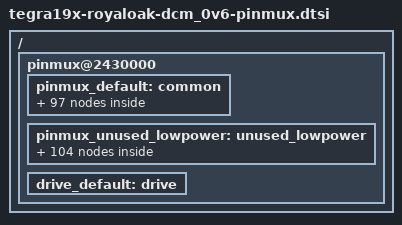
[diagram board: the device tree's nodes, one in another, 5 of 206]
/*This dtsi file was generated by dcm_0v6.xlsm Revision: 1.06 */
/*
 * Copyright (c) 2017, NVIDIA CORPORATION.  All rights reserved.
 *
 * This program is free software; you can redistribute it and/or modify
 * it under the terms of the GNU General Public License as published by
 * the Free Software Foundation; either version 2 of the License, or
 * (at your option) any later version.
 *
 * This program is distributed in the hope that it will be useful, but WITHOUT
 * ANY WARRANTY; without even the implied warranty of MERCHANTABILITY or
 * FITNESS FOR A PARTICULAR PURPOSE.  See the GNU General Public License for
 * more details.
 */

#include <dt-bindings/pinctrl/pinctrl-tegra.h>

/ {
	pinmux@2430000 {
		pinctrl-names = "default", "drive", "unused";
		pinctrl-0 = <&pinmux_default>;
		pinctrl-1 = <&drive_default>;
		pinctrl-2 = <&pinmux_unused_lowpower>;

		pinmux_default: common {
			/* SFIO Pin Configuration */
			eqos_txc_pe0 {
				nvidia,pins = "eqos_txc_pe0";
				nvidia,function = "eqos";
				nvidia,pull = <TEGRA_PIN_PULL_NONE>;
				nvidia,tristate = <TEGRA_PIN_DISABLE>;
				nvidia,enable-input = <TEGRA_PIN_DISABLE>;
			};

			eqos_td0_pe1 {
				nvidia,pins = "eqos_td0_pe1";
				nvidia,function = "eqos";
				nvidia,pull = <TEGRA_PIN_PULL_NONE>;
				nvidia,tristate = <TEGRA_PIN_DISABLE>;
				nvidia,enable-input = <TEGRA_PIN_DISABLE>;
			};

			eqos_td1_pe2 {
				nvidia,pins = "eqos_td1_pe2";
				nvidia,function = "eqos";
				nvidia,pull = <TEGRA_PIN_PULL_NONE>;
				nvidia,tristate = <TEGRA_PIN_DISABLE>;
				nvidia,enable-input = <TEGRA_PIN_DISABLE>;
			};

			eqos_td2_pe3 {
				nvidia,pins = "eqos_td2_pe3";
				nvidia,function = "eqos";
				nvidia,pull = <TEGRA_PIN_PULL_NONE>;
				nvidia,tristate = <TEGRA_PIN_DISABLE>;
				nvidia,enable-input = <TEGRA_PIN_DISABLE>;
			};

			eqos_td3_pe4 {
				nvidia,pins = "eqos_td3_pe4";
				nvidia,function = "eqos";
				nvidia,pull = <TEGRA_PIN_PULL_NONE>;
				nvidia,tristate = <TEGRA_PIN_DISABLE>;
				nvidia,enable-input = <TEGRA_PIN_DISABLE>;
			};

			eqos_tx_ctl_pe5 {
				nvidia,pins = "eqos_tx_ctl_pe5";
				nvidia,function = "eqos";
				nvidia,pull = <TEGRA_PIN_PULL_NONE>;
				nvidia,tristate = <TEGRA_PIN_DISABLE>;
				nvidia,enable-input = <TEGRA_PIN_DISABLE>;
			};

			eqos_rd0_pe6 {
				nvidia,pins = "eqos_rd0_pe6";
				nvidia,function = "eqos";
				nvidia,pull = <TEGRA_PIN_PULL_NONE>;
				nvidia,tristate = <TEGRA_PIN_ENABLE>;
				nvidia,enable-input = <TEGRA_PIN_ENABLE>;
			};

			eqos_rd1_pe7 {
				nvidia,pins = "eqos_rd1_pe7";
				nvidia,function = "eqos";
				nvidia,pull = <TEGRA_PIN_PULL_NONE>;
				nvidia,tristate = <TEGRA_PIN_ENABLE>;
				nvidia,enable-input = <TEGRA_PIN_ENABLE>;
			};

			eqos_rd2_pf0 {
				nvidia,pins = "eqos_rd2_pf0";
				nvidia,function = "eqos";
				nvidia,pull = <TEGRA_PIN_PULL_NONE>;
				nvidia,tristate = <TEGRA_PIN_ENABLE>;
				nvidia,enable-input = <TEGRA_PIN_ENABLE>;
			};

			eqos_rd3_pf1 {
				nvidia,pins = "eqos_rd3_pf1";
				nvidia,function = "eqos";
				nvidia,pull = <TEGRA_PIN_PULL_NONE>;
				nvidia,tristate = <TEGRA_PIN_ENABLE>;
				nvidia,enable-input = <TEGRA_PIN_ENABLE>;
			};

			eqos_rx_ctl_pf2 {
				nvidia,pins = "eqos_rx_ctl_pf2";
				nvidia,function = "eqos";
				nvidia,pull = <TEGRA_PIN_PULL_NONE>;
				nvidia,tristate = <TEGRA_PIN_ENABLE>;
				nvidia,enable-input = <TEGRA_PIN_ENABLE>;
			};

			eqos_rxc_pf3 {
				nvidia,pins = "eqos_rxc_pf3";
				nvidia,function = "eqos";
				nvidia,pull = <TEGRA_PIN_PULL_NONE>;
				nvidia,tristate = <TEGRA_PIN_ENABLE>;
				nvidia,enable-input = <TEGRA_PIN_ENABLE>;
			};

			eqos_sma_mdio_pf4 {
				nvidia,pins = "eqos_sma_mdio_pf4";
				nvidia,function = "eqos";
				nvidia,pull = <TEGRA_PIN_PULL_NONE>;
				nvidia,tristate = <TEGRA_PIN_DISABLE>;
				nvidia,enable-input = <TEGRA_PIN_ENABLE>;
			};

			eqos_sma_mdc_pf5 {
				nvidia,pins = "eqos_sma_mdc_pf5";
				nvidia,function = "eqos";
				nvidia,pull = <TEGRA_PIN_PULL_NONE>;
				nvidia,tristate = <TEGRA_PIN_DISABLE>;
				nvidia,enable-input = <TEGRA_PIN_DISABLE>;
			};

			qspi0_sck_pc0 {
				nvidia,pins = "qspi0_sck_pc0";
				nvidia,function = "qspi0";
				nvidia,pull = <TEGRA_PIN_PULL_NONE>;
				nvidia,tristate = <TEGRA_PIN_DISABLE>;
				nvidia,enable-input = <TEGRA_PIN_ENABLE>;
				nvidia,loopback = <TEGRA_PIN_ENABLE>;
			};

			qspi0_cs_n_pc1 {
				nvidia,pins = "qspi0_cs_n_pc1";
				nvidia,function = "qspi0";
				nvidia,pull = <TEGRA_PIN_PULL_NONE>;
				nvidia,tristate = <TEGRA_PIN_DISABLE>;
				nvidia,enable-input = <TEGRA_PIN_DISABLE>;
			};

			qspi0_io0_pc2 {
				nvidia,pins = "qspi0_io0_pc2";
				nvidia,function = "qspi0";
				nvidia,pull = <TEGRA_PIN_PULL_NONE>;
				nvidia,tristate = <TEGRA_PIN_DISABLE>;
				nvidia,enable-input = <TEGRA_PIN_ENABLE>;
			};

			qspi0_io1_pc3 {
				nvidia,pins = "qspi0_io1_pc3";
				nvidia,function = "qspi0";
				nvidia,pull = <TEGRA_PIN_PULL_NONE>;
				nvidia,tristate = <TEGRA_PIN_DISABLE>;
				nvidia,enable-input = <TEGRA_PIN_ENABLE>;
			};

			qspi0_io2_pc4 {
				nvidia,pins = "qspi0_io2_pc4";
				nvidia,function = "qspi0";
				nvidia,pull = <TEGRA_PIN_PULL_NONE>;
				nvidia,tristate = <TEGRA_PIN_DISABLE>;
				nvidia,enable-input = <TEGRA_PIN_ENABLE>;
			};

			qspi0_io3_pc5 {
				nvidia,pins = "qspi0_io3_pc5";
				nvidia,function = "qspi0";
				nvidia,pull = <TEGRA_PIN_PULL_NONE>;
				nvidia,tristate = <TEGRA_PIN_DISABLE>;
				nvidia,enable-input = <TEGRA_PIN_ENABLE>;
			};

			qspi1_sck_pc6 {
				nvidia,pins = "qspi1_sck_pc6";
				nvidia,function = "qspi1";
				nvidia,pull = <TEGRA_PIN_PULL_NONE>;
				nvidia,tristate = <TEGRA_PIN_DISABLE>;
				nvidia,enable-input = <TEGRA_PIN_ENABLE>;
				nvidia,loopback = <TEGRA_PIN_ENABLE>;
			};

			qspi1_cs_n_pc7 {
				nvidia,pins = "qspi1_cs_n_pc7";
				nvidia,function = "qspi1";
				nvidia,pull = <TEGRA_PIN_PULL_NONE>;
				nvidia,tristate = <TEGRA_PIN_DISABLE>;
				nvidia,enable-input = <TEGRA_PIN_DISABLE>;
			};

			qspi1_io0_pd0 {
				nvidia,pins = "qspi1_io0_pd0";
				nvidia,function = "qspi1";
				nvidia,pull = <TEGRA_PIN_PULL_NONE>;
				nvidia,tristate = <TEGRA_PIN_DISABLE>;
				nvidia,enable-input = <TEGRA_PIN_ENABLE>;
			};

			qspi1_io1_pd1 {
				nvidia,pins = "qspi1_io1_pd1";
				nvidia,function = "qspi1";
				nvidia,pull = <TEGRA_PIN_PULL_NONE>;
				nvidia,tristate = <TEGRA_PIN_DISABLE>;
				nvidia,enable-input = <TEGRA_PIN_ENABLE>;
			};

			qspi1_io2_pd2 {
				nvidia,pins = "qspi1_io2_pd2";
				nvidia,function = "qspi1";
				nvidia,pull = <TEGRA_PIN_PULL_NONE>;
				nvidia,tristate = <TEGRA_PIN_DISABLE>;
				nvidia,enable-input = <TEGRA_PIN_ENABLE>;
			};

			qspi1_io3_pd3 {
				nvidia,pins = "qspi1_io3_pd3";
				nvidia,function = "qspi1";
				nvidia,pull = <TEGRA_PIN_PULL_NONE>;
				nvidia,tristate = <TEGRA_PIN_DISABLE>;
				nvidia,enable-input = <TEGRA_PIN_ENABLE>;
			};

			sdmmc4_clk {
				nvidia,pins = "sdmmc4_clk";
				nvidia,function = "sdmmc4";
				nvidia,pull = <TEGRA_PIN_PULL_NONE>;
				nvidia,tristate = <TEGRA_PIN_DISABLE>;
				nvidia,enable-input = <TEGRA_PIN_ENABLE>;
				nvidia,loopback = <TEGRA_PIN_ENABLE>;
			};

			sdmmc4_cmd {
				nvidia,pins = "sdmmc4_cmd";
				nvidia,function = "sdmmc4";
				nvidia,pull = <TEGRA_PIN_PULL_NONE>;
				nvidia,tristate = <TEGRA_PIN_DISABLE>;
				nvidia,enable-input = <TEGRA_PIN_ENABLE>;
			};

			sdmmc4_dat0 {
				nvidia,pins = "sdmmc4_dat0";
				nvidia,function = "sdmmc4";
				nvidia,pull = <TEGRA_PIN_PULL_UP>;
				nvidia,tristate = <TEGRA_PIN_DISABLE>;
				nvidia,enable-input = <TEGRA_PIN_ENABLE>;
			};

			sdmmc4_dat1 {
				nvidia,pins = "sdmmc4_dat1";
				nvidia,function = "sdmmc4";
				nvidia,pull = <TEGRA_PIN_PULL_UP>;
				nvidia,tristate = <TEGRA_PIN_DISABLE>;
				nvidia,enable-input = <TEGRA_PIN_ENABLE>;
			};

			sdmmc4_dat2 {
				nvidia,pins = "sdmmc4_dat2";
				nvidia,function = "sdmmc4";
				nvidia,pull = <TEGRA_PIN_PULL_UP>;
				nvidia,tristate = <TEGRA_PIN_DISABLE>;
				nvidia,enable-input = <TEGRA_PIN_ENABLE>;
			};

			sdmmc4_dat3 {
				nvidia,pins = "sdmmc4_dat3";
				nvidia,function = "sdmmc4";
				nvidia,pull = <TEGRA_PIN_PULL_UP>;
				nvidia,tristate = <TEGRA_PIN_DISABLE>;
				nvidia,enable-input = <TEGRA_PIN_ENABLE>;
			};

			sdmmc4_dat4 {
				nvidia,pins = "sdmmc4_dat4";
				nvidia,function = "sdmmc4";
				nvidia,pull = <TEGRA_PIN_PULL_UP>;
				nvidia,tristate = <TEGRA_PIN_DISABLE>;
				nvidia,enable-input = <TEGRA_PIN_ENABLE>;
			};

			sdmmc4_dat5 {
				nvidia,pins = "sdmmc4_dat5";
				nvidia,function = "sdmmc4";
				nvidia,pull = <TEGRA_PIN_PULL_UP>;
				nvidia,tristate = <TEGRA_PIN_DISABLE>;
				nvidia,enable-input = <TEGRA_PIN_ENABLE>;
			};

			sdmmc4_dat6 {
				nvidia,pins = "sdmmc4_dat6";
				nvidia,function = "sdmmc4";
				nvidia,pull = <TEGRA_PIN_PULL_UP>;
				nvidia,tristate = <TEGRA_PIN_DISABLE>;
				nvidia,enable-input = <TEGRA_PIN_ENABLE>;
			};

			sdmmc4_dat7 {
				nvidia,pins = "sdmmc4_dat7";
				nvidia,function = "sdmmc4";
				nvidia,pull = <TEGRA_PIN_PULL_UP>;
				nvidia,tristate = <TEGRA_PIN_DISABLE>;
				nvidia,enable-input = <TEGRA_PIN_ENABLE>;
			};

			sdmmc4_dqs {
				nvidia,pins = "sdmmc4_dqs";
				nvidia,function = "sdmmc4";
				nvidia,pull = <TEGRA_PIN_PULL_NONE>;
				nvidia,tristate = <TEGRA_PIN_ENABLE>;
				nvidia,enable-input = <TEGRA_PIN_ENABLE>;
			};

			soc_gpio10_pg6 {
				nvidia,pins = "soc_gpio10_pg6";
				nvidia,function = "gp";
				nvidia,pull = <TEGRA_PIN_PULL_NONE>;
				nvidia,tristate = <TEGRA_PIN_ENABLE>;
				nvidia,enable-input = <TEGRA_PIN_DISABLE>;
				nvidia,lpdr = <TEGRA_PIN_DISABLE>;
			};

			soc_gpio13_ph1 {
				nvidia,pins = "soc_gpio13_ph1";
				nvidia,function = "gp";
				nvidia,pull = <TEGRA_PIN_PULL_NONE>;
				nvidia,tristate = <TEGRA_PIN_ENABLE>;
				nvidia,enable-input = <TEGRA_PIN_DISABLE>;
				nvidia,lpdr = <TEGRA_PIN_DISABLE>;
			};

			gen1_i2c_scl_pi3 {
				nvidia,pins = "gen1_i2c_scl_pi3";
				nvidia,function = "i2c1";
				nvidia,pull = <TEGRA_PIN_PULL_NONE>;
				nvidia,tristate = <TEGRA_PIN_DISABLE>;
				nvidia,enable-input = <TEGRA_PIN_ENABLE>;
				nvidia,io-high-voltage = <TEGRA_PIN_DISABLE>;
				nvidia,lpdr = <TEGRA_PIN_DISABLE>;
			};

			gen1_i2c_sda_pi4 {
				nvidia,pins = "gen1_i2c_sda_pi4";
				nvidia,function = "i2c1";
				nvidia,pull = <TEGRA_PIN_PULL_NONE>;
				nvidia,tristate = <TEGRA_PIN_DISABLE>;
				nvidia,enable-input = <TEGRA_PIN_ENABLE>;
				nvidia,io-high-voltage = <TEGRA_PIN_DISABLE>;
				nvidia,lpdr = <TEGRA_PIN_DISABLE>;
			};

			gp_pwm2_px2 {
				nvidia,pins = "gp_pwm2_px2";
				nvidia,function = "gp";
				nvidia,pull = <TEGRA_PIN_PULL_NONE>;
				nvidia,tristate = <TEGRA_PIN_ENABLE>;
				nvidia,enable-input = <TEGRA_PIN_DISABLE>;
				nvidia,lpdr = <TEGRA_PIN_DISABLE>;
			};

			gp_pwm3_px3 {
				nvidia,pins = "gp_pwm3_px3";
				nvidia,function = "gp";
				nvidia,pull = <TEGRA_PIN_PULL_NONE>;
				nvidia,tristate = <TEGRA_PIN_ENABLE>;
				nvidia,enable-input = <TEGRA_PIN_DISABLE>;
				nvidia,lpdr = <TEGRA_PIN_DISABLE>;
			};

			uart2_tx_px4 {
				nvidia,pins = "uart2_tx_px4";
				nvidia,function = "uartb";
				nvidia,pull = <TEGRA_PIN_PULL_NONE>;
				nvidia,tristate = <TEGRA_PIN_DISABLE>;
				nvidia,enable-input = <TEGRA_PIN_DISABLE>;
				nvidia,io-high-voltage = <TEGRA_PIN_DISABLE>;
				nvidia,lpdr = <TEGRA_PIN_DISABLE>;
			};

			uart2_rx_px5 {
				nvidia,pins = "uart2_rx_px5";
				nvidia,function = "uartb";
				nvidia,pull = <TEGRA_PIN_PULL_UP>;
				nvidia,tristate = <TEGRA_PIN_ENABLE>;
				nvidia,enable-input = <TEGRA_PIN_ENABLE>;
				nvidia,io-high-voltage = <TEGRA_PIN_DISABLE>;
				nvidia,lpdr = <TEGRA_PIN_DISABLE>;
			};

			spi1_sck_pz3 {
				nvidia,pins = "spi1_sck_pz3";
				nvidia,function = "spi1";
				nvidia,pull = <TEGRA_PIN_PULL_DOWN>;
				nvidia,tristate = <TEGRA_PIN_DISABLE>;
				nvidia,enable-input = <TEGRA_PIN_DISABLE>;
				nvidia,lpdr = <TEGRA_PIN_DISABLE>;
			};

			spi1_miso_pz4 {
				nvidia,pins = "spi1_miso_pz4";
				nvidia,function = "spi1";
				nvidia,pull = <TEGRA_PIN_PULL_DOWN>;
				nvidia,tristate = <TEGRA_PIN_ENABLE>;
				nvidia,enable-input = <TEGRA_PIN_ENABLE>;
				nvidia,lpdr = <TEGRA_PIN_DISABLE>;
			};

			spi1_mosi_pz5 {
				nvidia,pins = "spi1_mosi_pz5";
				nvidia,function = "spi1";
				nvidia,pull = <TEGRA_PIN_PULL_DOWN>;
				nvidia,tristate = <TEGRA_PIN_DISABLE>;
				nvidia,enable-input = <TEGRA_PIN_DISABLE>;
				nvidia,lpdr = <TEGRA_PIN_DISABLE>;
			};

			spi1_cs0_pz6 {
				nvidia,pins = "spi1_cs0_pz6";
				nvidia,function = "spi1";
				nvidia,pull = <TEGRA_PIN_PULL_NONE>;
				nvidia,tristate = <TEGRA_PIN_DISABLE>;
				nvidia,enable-input = <TEGRA_PIN_DISABLE>;
				nvidia,lpdr = <TEGRA_PIN_DISABLE>;
			};

			shutdown_n {
				nvidia,pins = "shutdown_n";
				nvidia,function = "shutdown";
				nvidia,pull = <TEGRA_PIN_PULL_NONE>;
				nvidia,tristate = <TEGRA_PIN_DISABLE>;
				nvidia,enable-input = <TEGRA_PIN_DISABLE>;
				nvidia,io-high-voltage = <TEGRA_PIN_DISABLE>;
				nvidia,lpdr = <TEGRA_PIN_ENABLE>;
			};

			pwr_i2c_scl_pee5 {
				nvidia,pins = "pwr_i2c_scl_pee5";
				nvidia,function = "i2c5";
				nvidia,pull = <TEGRA_PIN_PULL_NONE>;
				nvidia,tristate = <TEGRA_PIN_DISABLE>;
				nvidia,enable-input = <TEGRA_PIN_ENABLE>;
				nvidia,io-high-voltage = <TEGRA_PIN_DISABLE>;
				nvidia,lpdr = <TEGRA_PIN_DISABLE>;
			};

			pwr_i2c_sda_pee6 {
				nvidia,pins = "pwr_i2c_sda_pee6";
				nvidia,function = "i2c5";
				nvidia,pull = <TEGRA_PIN_PULL_NONE>;
				nvidia,tristate = <TEGRA_PIN_DISABLE>;
				nvidia,enable-input = <TEGRA_PIN_ENABLE>;
				nvidia,io-high-voltage = <TEGRA_PIN_DISABLE>;
				nvidia,lpdr = <TEGRA_PIN_DISABLE>;
			};

			batt_oc_pee3 {
				nvidia,pins = "batt_oc_pee3";
				nvidia,function = "soc";
				nvidia,pull = <TEGRA_PIN_PULL_NONE>;
				nvidia,tristate = <TEGRA_PIN_ENABLE>;
				nvidia,enable-input = <TEGRA_PIN_ENABLE>;
				nvidia,lpdr = <TEGRA_PIN_DISABLE>;
			};

			spi2_sck_pcc0 {
				nvidia,pins = "spi2_sck_pcc0";
				nvidia,function = "spi2";
				nvidia,pull = <TEGRA_PIN_PULL_NONE>;
				nvidia,tristate = <TEGRA_PIN_DISABLE>;
				nvidia,enable-input = <TEGRA_PIN_DISABLE>;
				nvidia,io-high-voltage = <TEGRA_PIN_DISABLE>;
				nvidia,lpdr = <TEGRA_PIN_DISABLE>;
			};

			spi2_miso_pcc1 {
				nvidia,pins = "spi2_miso_pcc1";
				nvidia,function = "spi2";
				nvidia,pull = <TEGRA_PIN_PULL_NONE>;
				nvidia,tristate = <TEGRA_PIN_ENABLE>;
				nvidia,enable-input = <TEGRA_PIN_ENABLE>;
				nvidia,io-high-voltage = <TEGRA_PIN_DISABLE>;
				nvidia,lpdr = <TEGRA_PIN_DISABLE>;
			};

			spi2_mosi_pcc2 {
				nvidia,pins = "spi2_mosi_pcc2";
				nvidia,function = "spi2";
				nvidia,pull = <TEGRA_PIN_PULL_NONE>;
				nvidia,tristate = <TEGRA_PIN_DISABLE>;
				nvidia,enable-input = <TEGRA_PIN_DISABLE>;
				nvidia,io-high-voltage = <TEGRA_PIN_DISABLE>;
				nvidia,lpdr = <TEGRA_PIN_DISABLE>;
			};

			spi2_cs0_pcc3 {
				nvidia,pins = "spi2_cs0_pcc3";
				nvidia,function = "spi2";
				nvidia,pull = <TEGRA_PIN_PULL_NONE>;
				nvidia,tristate = <TEGRA_PIN_DISABLE>;
				nvidia,enable-input = <TEGRA_PIN_DISABLE>;
				nvidia,io-high-voltage = <TEGRA_PIN_DISABLE>;
				nvidia,lpdr = <TEGRA_PIN_DISABLE>;
			};

			touch_clk_pcc4 {
				nvidia,pins = "touch_clk_pcc4";
				nvidia,function = "gp";
				nvidia,pull = <TEGRA_PIN_PULL_NONE>;
				nvidia,tristate = <TEGRA_PIN_DISABLE>;
				nvidia,enable-input = <TEGRA_PIN_DISABLE>;
				nvidia,lpdr = <TEGRA_PIN_DISABLE>;
			};

			uart3_tx_pcc5 {
				nvidia,pins = "uart3_tx_pcc5";
				nvidia,function = "uartc";
				nvidia,pull = <TEGRA_PIN_PULL_NONE>;
				nvidia,tristate = <TEGRA_PIN_DISABLE>;
				nvidia,enable-input = <TEGRA_PIN_DISABLE>;
				nvidia,io-high-voltage = <TEGRA_PIN_DISABLE>;
				nvidia,lpdr = <TEGRA_PIN_DISABLE>;
			};

			uart3_rx_pcc6 {
				nvidia,pins = "uart3_rx_pcc6";
				nvidia,function = "uartc";
				nvidia,pull = <TEGRA_PIN_PULL_UP>;
				nvidia,tristate = <TEGRA_PIN_ENABLE>;
				nvidia,enable-input = <TEGRA_PIN_ENABLE>;
				nvidia,io-high-voltage = <TEGRA_PIN_DISABLE>;
				nvidia,lpdr = <TEGRA_PIN_DISABLE>;
			};

			gen2_i2c_scl_pcc7 {
				nvidia,pins = "gen2_i2c_scl_pcc7";
				nvidia,function = "i2c2";
				nvidia,pull = <TEGRA_PIN_PULL_NONE>;
				nvidia,tristate = <TEGRA_PIN_DISABLE>;
				nvidia,enable-input = <TEGRA_PIN_ENABLE>;
				nvidia,io-high-voltage = <TEGRA_PIN_DISABLE>;
				nvidia,lpdr = <TEGRA_PIN_ENABLE>;
			};

			gen2_i2c_sda_pdd0 {
				nvidia,pins = "gen2_i2c_sda_pdd0";
				nvidia,function = "i2c2";
				nvidia,pull = <TEGRA_PIN_PULL_NONE>;
				nvidia,tristate = <TEGRA_PIN_DISABLE>;
				nvidia,enable-input = <TEGRA_PIN_ENABLE>;
				nvidia,io-high-voltage = <TEGRA_PIN_DISABLE>;
				nvidia,lpdr = <TEGRA_PIN_ENABLE>;
			};

			soc_gpio07_pp7 {
				nvidia,pins = "soc_gpio07_pp7";
				nvidia,function = "soc";
				nvidia,pull = <TEGRA_PIN_PULL_UP>;
				nvidia,tristate = <TEGRA_PIN_ENABLE>;
				nvidia,enable-input = <TEGRA_PIN_ENABLE>;
				nvidia,io-high-voltage = <TEGRA_PIN_DISABLE>;
				nvidia,lpdr = <TEGRA_PIN_DISABLE>;
			};

			soc_gpio22_pq2 {
				nvidia,pins = "soc_gpio22_pq2";
				nvidia,function = "nv";
				nvidia,pull = <TEGRA_PIN_PULL_NONE>;
				nvidia,tristate = <TEGRA_PIN_ENABLE>;
				nvidia,enable-input = <TEGRA_PIN_ENABLE>;
				nvidia,lpdr = <TEGRA_PIN_DISABLE>;
			};

			soc_gpio54_pn1 {
				nvidia,pins = "soc_gpio54_pn1";
				nvidia,function = "gp";
				nvidia,pull = <TEGRA_PIN_PULL_NONE>;
				nvidia,tristate = <TEGRA_PIN_DISABLE>;
				nvidia,enable-input = <TEGRA_PIN_DISABLE>;
				nvidia,lpdr = <TEGRA_PIN_DISABLE>;
			};

			/* GPIO Pin Configuration */
			soc_gpio30_ps5 {
				nvidia,pins = "soc_gpio30_ps5";
				nvidia,function = "rsvd0";
				nvidia,pull = <TEGRA_PIN_PULL_UP>;
				nvidia,tristate = <TEGRA_PIN_ENABLE>;
				nvidia,enable-input = <TEGRA_PIN_ENABLE>;
				nvidia,lpdr = <TEGRA_PIN_DISABLE>;
			};

			soc_gpio31_ps6 {
				nvidia,pins = "soc_gpio31_ps6";
				nvidia,function = "rsvd0";
				nvidia,pull = <TEGRA_PIN_PULL_UP>;
				nvidia,tristate = <TEGRA_PIN_ENABLE>;
				nvidia,enable-input = <TEGRA_PIN_ENABLE>;
				nvidia,lpdr = <TEGRA_PIN_DISABLE>;
			};

			soc_gpio32_ps7 {
				nvidia,pins = "soc_gpio32_ps7";
				nvidia,function = "rsvd0";
				nvidia,pull = <TEGRA_PIN_PULL_UP>;
				nvidia,tristate = <TEGRA_PIN_ENABLE>;
				nvidia,enable-input = <TEGRA_PIN_ENABLE>;
				nvidia,lpdr = <TEGRA_PIN_DISABLE>;
			};

			soc_gpio00_pg0 {
				nvidia,pins = "soc_gpio00_pg0";
				nvidia,function = "rsvd0";
				nvidia,pull = <TEGRA_PIN_PULL_NONE>;
				nvidia,tristate = <TEGRA_PIN_ENABLE>;
				nvidia,enable-input = <TEGRA_PIN_ENABLE>;
				nvidia,lpdr = <TEGRA_PIN_DISABLE>;
			};

			soc_gpio01_pg1 {
				nvidia,pins = "soc_gpio01_pg1";
				nvidia,function = "rsvd0";
				nvidia,pull = <TEGRA_PIN_PULL_NONE>;
				nvidia,tristate = <TEGRA_PIN_ENABLE>;
				nvidia,enable-input = <TEGRA_PIN_ENABLE>;
				nvidia,lpdr = <TEGRA_PIN_DISABLE>;
			};

			soc_gpio08_pg4 {
				nvidia,pins = "soc_gpio08_pg4";
				nvidia,function = "rsvd0";
				nvidia,pull = <TEGRA_PIN_PULL_NONE>;
				nvidia,tristate = <TEGRA_PIN_ENABLE>;
				nvidia,enable-input = <TEGRA_PIN_ENABLE>;
				nvidia,lpdr = <TEGRA_PIN_DISABLE>;
			};

			soc_gpio09_pg5 {
				nvidia,pins = "soc_gpio09_pg5";
				nvidia,function = "rsvd0";
				nvidia,pull = <TEGRA_PIN_PULL_NONE>;
				nvidia,tristate = <TEGRA_PIN_DISABLE>;
				nvidia,enable-input = <TEGRA_PIN_DISABLE>;
				nvidia,lpdr = <TEGRA_PIN_DISABLE>;
			};

			soc_gpio14_ph2 {
				nvidia,pins = "soc_gpio14_ph2";
				nvidia,function = "rsvd0";
				nvidia,pull = <TEGRA_PIN_PULL_NONE>;
				nvidia,tristate = <TEGRA_PIN_ENABLE>;
				nvidia,enable-input = <TEGRA_PIN_ENABLE>;
				nvidia,lpdr = <TEGRA_PIN_DISABLE>;
			};

			gpu_pwr_req_px0 {
				nvidia,pins = "gpu_pwr_req_px0";
				nvidia,function = "rsvd0";
				nvidia,pull = <TEGRA_PIN_PULL_NONE>;
				nvidia,tristate = <TEGRA_PIN_DISABLE>;
				nvidia,enable-input = <TEGRA_PIN_DISABLE>;
				nvidia,lpdr = <TEGRA_PIN_DISABLE>;
			};

			cv_pwr_req_px1 {
				nvidia,pins = "cv_pwr_req_px1";
				nvidia,function = "rsvd0";
				nvidia,pull = <TEGRA_PIN_PULL_NONE>;
				nvidia,tristate = <TEGRA_PIN_DISABLE>;
				nvidia,enable-input = <TEGRA_PIN_DISABLE>;
				nvidia,lpdr = <TEGRA_PIN_DISABLE>;
			};

			usb_vbus_en0_pz1 {
				nvidia,pins = "usb_vbus_en0_pz1";
				nvidia,function = "rsvd1";
				nvidia,pull = <TEGRA_PIN_PULL_NONE>;
				nvidia,tristate = <TEGRA_PIN_DISABLE>;
				nvidia,enable-input = <TEGRA_PIN_DISABLE>;
				nvidia,io-high-voltage = <TEGRA_PIN_DISABLE>;
				nvidia,lpdr = <TEGRA_PIN_DISABLE>;
			};

			usb_vbus_en1_pz2 {
				nvidia,pins = "usb_vbus_en1_pz2";
				nvidia,function = "rsvd1";
				nvidia,pull = <TEGRA_PIN_PULL_NONE>;
				nvidia,tristate = <TEGRA_PIN_ENABLE>;
				nvidia,enable-input = <TEGRA_PIN_ENABLE>;
				nvidia,io-high-voltage = <TEGRA_PIN_DISABLE>;
				nvidia,lpdr = <TEGRA_PIN_DISABLE>;
			};

			safe_state_pee0 {
				nvidia,pins = "safe_state_pee0";
				nvidia,function = "rsvd1";
				nvidia,pull = <TEGRA_PIN_PULL_UP>;
				nvidia,tristate = <TEGRA_PIN_DISABLE>;
				nvidia,enable-input = <TEGRA_PIN_DISABLE>;
				nvidia,io-high-voltage = <TEGRA_PIN_DISABLE>;
				nvidia,lpdr = <TEGRA_PIN_DISABLE>;
			};

			power_on_pee4 {
				nvidia,pins = "power_on_pee4";
				nvidia,function = "rsvd0";
				nvidia,pull = <TEGRA_PIN_PULL_NONE>;
				nvidia,tristate = <TEGRA_PIN_ENABLE>;
				nvidia,enable-input = <TEGRA_PIN_ENABLE>;
				nvidia,lpdr = <TEGRA_PIN_DISABLE>;
			};

			can0_stb_paa4 {
				nvidia,pins = "can0_stb_paa4";
				nvidia,function = "rsvd0";
				nvidia,pull = <TEGRA_PIN_PULL_NONE>;
				nvidia,tristate = <TEGRA_PIN_DISABLE>;
				nvidia,enable-input = <TEGRA_PIN_DISABLE>;
			};

			can0_err_paa7 {
				nvidia,pins = "can0_err_paa7";
				nvidia,function = "rsvd0";
				nvidia,pull = <TEGRA_PIN_PULL_UP>;
				nvidia,tristate = <TEGRA_PIN_DISABLE>;
				nvidia,enable-input = <TEGRA_PIN_ENABLE>;
			};

			can1_en_pbb1 {
				nvidia,pins = "can1_en_pbb1";
				nvidia,function = "rsvd0";
				nvidia,pull = <TEGRA_PIN_PULL_NONE>;
				nvidia,tristate = <TEGRA_PIN_ENABLE>;
				nvidia,enable-input = <TEGRA_PIN_DISABLE>;
			};

			can1_wake_pbb2 {
				nvidia,pins = "can1_wake_pbb2";
				nvidia,function = "rsvd0";
				nvidia,pull = <TEGRA_PIN_PULL_NONE>;
				nvidia,tristate = <TEGRA_PIN_ENABLE>;
				nvidia,enable-input = <TEGRA_PIN_ENABLE>;
			};

			soc_gpio04_pp4 {
				nvidia,pins = "soc_gpio04_pp4";
				nvidia,function = "rsvd0";
				nvidia,pull = <TEGRA_PIN_PULL_NONE>;
				nvidia,tristate = <TEGRA_PIN_ENABLE>;
				nvidia,enable-input = <TEGRA_PIN_ENABLE>;
				nvidia,lpdr = <TEGRA_PIN_DISABLE>;
			};

			soc_gpio05_pp5 {
				nvidia,pins = "soc_gpio05_pp5";
				nvidia,function = "rsvd0";
				nvidia,pull = <TEGRA_PIN_PULL_UP>;
				nvidia,tristate = <TEGRA_PIN_ENABLE>;
				nvidia,enable-input = <TEGRA_PIN_ENABLE>;
				nvidia,lpdr = <TEGRA_PIN_DISABLE>;
			};

			soc_gpio06_pp6 {
				nvidia,pins = "soc_gpio06_pp6";
				nvidia,function = "rsvd0";
				nvidia,pull = <TEGRA_PIN_PULL_NONE>;
				nvidia,tristate = <TEGRA_PIN_ENABLE>;
				nvidia,enable-input = <TEGRA_PIN_ENABLE>;
				nvidia,lpdr = <TEGRA_PIN_DISABLE>;
			};

			soc_gpio20_pq0 {
				nvidia,pins = "soc_gpio20_pq0";
				nvidia,function = "rsvd0";
				nvidia,pull = <TEGRA_PIN_PULL_NONE>;
				nvidia,tristate = <TEGRA_PIN_ENABLE>;
				nvidia,enable-input = <TEGRA_PIN_ENABLE>;
				nvidia,lpdr = <TEGRA_PIN_DISABLE>;
			};

			soc_gpio21_pq1 {
				nvidia,pins = "soc_gpio21_pq1";
				nvidia,function = "rsvd0";
				nvidia,pull = <TEGRA_PIN_PULL_UP>;
				nvidia,tristate = <TEGRA_PIN_ENABLE>;
				nvidia,enable-input = <TEGRA_PIN_ENABLE>;
				nvidia,lpdr = <TEGRA_PIN_DISABLE>;
			};

			soc_gpio40_pq4 {
				nvidia,pins = "soc_gpio40_pq4";
				nvidia,function = "rsvd2";
				nvidia,pull = <TEGRA_PIN_PULL_UP>;
				nvidia,tristate = <TEGRA_PIN_ENABLE>;
				nvidia,enable-input = <TEGRA_PIN_ENABLE>;
				nvidia,io-high-voltage = <TEGRA_PIN_ENABLE>;
				nvidia,lpdr = <TEGRA_PIN_DISABLE>;
			};

			dap6_sclk_pa0 {
				nvidia,pins = "dap6_sclk_pa0";
				nvidia,function = "rsvd2";
				nvidia,pull = <TEGRA_PIN_PULL_NONE>;
				nvidia,tristate = <TEGRA_PIN_ENABLE>;
				nvidia,enable-input = <TEGRA_PIN_DISABLE>;
			};

			dap6_din_pa2 {
				nvidia,pins = "dap6_din_pa2";
				nvidia,function = "rsvd2";
				nvidia,pull = <TEGRA_PIN_PULL_NONE>;
				nvidia,tristate = <TEGRA_PIN_ENABLE>;
				nvidia,enable-input = <TEGRA_PIN_DISABLE>;
			};

			cpu_pwr_req_0_pb0 {
				nvidia,pins = "cpu_pwr_req_0_pb0";
				nvidia,function = "rsvd0";
				nvidia,pull = <TEGRA_PIN_PULL_NONE>;
				nvidia,tristate = <TEGRA_PIN_DISABLE>;
				nvidia,enable-input = <TEGRA_PIN_DISABLE>;
				nvidia,lpdr = <TEGRA_PIN_DISABLE>;
			};

			cpu_pwr_req_1_pb1 {
				nvidia,pins = "cpu_pwr_req_1_pb1";
				nvidia,function = "rsvd0";
				nvidia,pull = <TEGRA_PIN_PULL_NONE>;
				nvidia,tristate = <TEGRA_PIN_DISABLE>;
				nvidia,enable-input = <TEGRA_PIN_DISABLE>;
				nvidia,lpdr = <TEGRA_PIN_DISABLE>;
			};

			dp_aux_ch3_hpd_pm3 {
				nvidia,pins = "dp_aux_ch3_hpd_pm3";
				nvidia,function = "rsvd2";
				nvidia,pull = <TEGRA_PIN_PULL_NONE>;
				nvidia,tristate = <TEGRA_PIN_DISABLE>;
				nvidia,enable-input = <TEGRA_PIN_DISABLE>;
				nvidia,io-high-voltage = <TEGRA_PIN_DISABLE>;
			};

			soc_gpio51_pm6 {
				nvidia,pins = "soc_gpio51_pm6";
				nvidia,function = "rsvd0";
				nvidia,pull = <TEGRA_PIN_PULL_NONE>;
				nvidia,tristate = <TEGRA_PIN_DISABLE>;
				nvidia,enable-input = <TEGRA_PIN_DISABLE>;
				nvidia,lpdr = <TEGRA_PIN_DISABLE>;
			};

			soc_gpio53_pn0 {
				nvidia,pins = "soc_gpio53_pn0";
				nvidia,function = "rsvd0";
				nvidia,pull = <TEGRA_PIN_PULL_NONE>;
				nvidia,tristate = <TEGRA_PIN_ENABLE>;
				nvidia,enable-input = <TEGRA_PIN_ENABLE>;
				nvidia,lpdr = <TEGRA_PIN_DISABLE>;
			};

			soc_gpio55_pn2 {
				nvidia,pins = "soc_gpio55_pn2";
				nvidia,function = "rsvd0";
				nvidia,pull = <TEGRA_PIN_PULL_NONE>;
				nvidia,tristate = <TEGRA_PIN_DISABLE>;
				nvidia,enable-input = <TEGRA_PIN_DISABLE>;
				nvidia,lpdr = <TEGRA_PIN_DISABLE>;
			};
		};

		pinmux_unused_lowpower: unused_lowpower {
			dap1_sclk_ps0 {
				nvidia,pins = "dap1_sclk_ps0";
				nvidia,function = "rsvd1";
				nvidia,pull = <TEGRA_PIN_PULL_DOWN>;
				nvidia,tristate = <TEGRA_PIN_ENABLE>;
				nvidia,enable-input = <TEGRA_PIN_ENABLE>;
				nvidia,lpdr = <TEGRA_PIN_DISABLE>;
			};

			dap1_dout_ps1 {
				nvidia,pins = "dap1_dout_ps1";
				nvidia,function = "rsvd1";
				nvidia,pull = <TEGRA_PIN_PULL_DOWN>;
				nvidia,tristate = <TEGRA_PIN_ENABLE>;
				nvidia,enable-input = <TEGRA_PIN_DISABLE>;
				nvidia,lpdr = <TEGRA_PIN_DISABLE>;
			};

			dap1_din_ps2 {
				nvidia,pins = "dap1_din_ps2";
				nvidia,function = "rsvd1";
				nvidia,pull = <TEGRA_PIN_PULL_DOWN>;
				nvidia,tristate = <TEGRA_PIN_ENABLE>;
				nvidia,enable-input = <TEGRA_PIN_DISABLE>;
				nvidia,lpdr = <TEGRA_PIN_DISABLE>;
			};

			dap1_fs_ps3 {
				nvidia,pins = "dap1_fs_ps3";
				nvidia,function = "rsvd1";
				nvidia,pull = <TEGRA_PIN_PULL_DOWN>;
				nvidia,tristate = <TEGRA_PIN_ENABLE>;
				nvidia,enable-input = <TEGRA_PIN_ENABLE>;
				nvidia,lpdr = <TEGRA_PIN_DISABLE>;
			};

			aud_mclk_ps4 {
				nvidia,pins = "aud_mclk_ps4";
				nvidia,function = "rsvd1";
				nvidia,pull = <TEGRA_PIN_PULL_DOWN>;
				nvidia,tristate = <TEGRA_PIN_ENABLE>;
				nvidia,enable-input = <TEGRA_PIN_DISABLE>;
				nvidia,lpdr = <TEGRA_PIN_DISABLE>;
			};

			soc_gpio33_pt0 {
				nvidia,pins = "soc_gpio33_pt0";
				nvidia,function = "rsvd0";
				nvidia,pull = <TEGRA_PIN_PULL_DOWN>;
				nvidia,tristate = <TEGRA_PIN_ENABLE>;
				nvidia,enable-input = <TEGRA_PIN_DISABLE>;
				nvidia,lpdr = <TEGRA_PIN_DISABLE>;
			};

			dap3_sclk_pt1 {
				nvidia,pins = "dap3_sclk_pt1";
				nvidia,function = "rsvd2";
				nvidia,pull = <TEGRA_PIN_PULL_DOWN>;
				nvidia,tristate = <TEGRA_PIN_ENABLE>;
				nvidia,enable-input = <TEGRA_PIN_DISABLE>;
				nvidia,lpdr = <TEGRA_PIN_DISABLE>;
			};

			dap3_dout_pt2 {
				nvidia,pins = "dap3_dout_pt2";
				nvidia,function = "rsvd2";
				nvidia,pull = <TEGRA_PIN_PULL_DOWN>;
				nvidia,tristate = <TEGRA_PIN_ENABLE>;
				nvidia,enable-input = <TEGRA_PIN_DISABLE>;
				nvidia,lpdr = <TEGRA_PIN_DISABLE>;
			};

			dap3_din_pt3 {
				nvidia,pins = "dap3_din_pt3";
				nvidia,function = "rsvd2";
				nvidia,pull = <TEGRA_PIN_PULL_DOWN>;
				nvidia,tristate = <TEGRA_PIN_ENABLE>;
				nvidia,enable-input = <TEGRA_PIN_DISABLE>;
				nvidia,lpdr = <TEGRA_PIN_DISABLE>;
			};

			dap3_fs_pt4 {
				nvidia,pins = "dap3_fs_pt4";
				nvidia,function = "rsvd2";
				nvidia,pull = <TEGRA_PIN_PULL_DOWN>;
				nvidia,tristate = <TEGRA_PIN_ENABLE>;
				nvidia,enable-input = <TEGRA_PIN_DISABLE>;
				nvidia,lpdr = <TEGRA_PIN_DISABLE>;
			};

			dap5_sclk_pt5 {
				nvidia,pins = "dap5_sclk_pt5";
				nvidia,function = "rsvd2";
				nvidia,pull = <TEGRA_PIN_PULL_DOWN>;
				nvidia,tristate = <TEGRA_PIN_ENABLE>;
				nvidia,enable-input = <TEGRA_PIN_DISABLE>;
				nvidia,lpdr = <TEGRA_PIN_DISABLE>;
			};

			dap5_dout_pt6 {
				nvidia,pins = "dap5_dout_pt6";
				nvidia,function = "rsvd2";
				nvidia,pull = <TEGRA_PIN_PULL_DOWN>;
				nvidia,tristate = <TEGRA_PIN_ENABLE>;
				nvidia,enable-input = <TEGRA_PIN_DISABLE>;
				nvidia,lpdr = <TEGRA_PIN_DISABLE>;
			};

			dap5_din_pt7 {
				nvidia,pins = "dap5_din_pt7";
				nvidia,function = "rsvd3";
				nvidia,pull = <TEGRA_PIN_PULL_DOWN>;
				nvidia,tristate = <TEGRA_PIN_ENABLE>;
				nvidia,enable-input = <TEGRA_PIN_DISABLE>;
				nvidia,lpdr = <TEGRA_PIN_DISABLE>;
			};

			dap5_fs_pu0 {
				nvidia,pins = "dap5_fs_pu0";
				nvidia,function = "rsvd3";
				nvidia,pull = <TEGRA_PIN_PULL_DOWN>;
				nvidia,tristate = <TEGRA_PIN_ENABLE>;
				nvidia,enable-input = <TEGRA_PIN_DISABLE>;
				nvidia,lpdr = <TEGRA_PIN_DISABLE>;
			};

			sdmmc1_clk_pj0 {
				nvidia,pins = "sdmmc1_clk_pj0";
				nvidia,function = "rsvd1";
				nvidia,pull = <TEGRA_PIN_PULL_DOWN>;
				nvidia,tristate = <TEGRA_PIN_ENABLE>;
				nvidia,enable-input = <TEGRA_PIN_DISABLE>;
				nvidia,loopback = <TEGRA_PIN_ENABLE>;
			};

			sdmmc1_cmd_pj1 {
				nvidia,pins = "sdmmc1_cmd_pj1";
				nvidia,function = "rsvd1";
				nvidia,pull = <TEGRA_PIN_PULL_DOWN>;
				nvidia,tristate = <TEGRA_PIN_ENABLE>;
				nvidia,enable-input = <TEGRA_PIN_DISABLE>;
			};

			sdmmc1_dat0_pj2 {
				nvidia,pins = "sdmmc1_dat0_pj2";
				nvidia,function = "rsvd1";
				nvidia,pull = <TEGRA_PIN_PULL_DOWN>;
				nvidia,tristate = <TEGRA_PIN_ENABLE>;
				nvidia,enable-input = <TEGRA_PIN_DISABLE>;
			};

			sdmmc1_dat1_pj3 {
				nvidia,pins = "sdmmc1_dat1_pj3";
				nvidia,function = "rsvd1";
				nvidia,pull = <TEGRA_PIN_PULL_DOWN>;
				nvidia,tristate = <TEGRA_PIN_ENABLE>;
				nvidia,enable-input = <TEGRA_PIN_DISABLE>;
			};

			sdmmc1_dat2_pj4 {
				nvidia,pins = "sdmmc1_dat2_pj4";
				nvidia,function = "rsvd1";
				nvidia,pull = <TEGRA_PIN_PULL_DOWN>;
				nvidia,tristate = <TEGRA_PIN_ENABLE>;
				nvidia,enable-input = <TEGRA_PIN_DISABLE>;
			};

			sdmmc1_dat3_pj5 {
				nvidia,pins = "sdmmc1_dat3_pj5";
				nvidia,function = "rsvd1";
				nvidia,pull = <TEGRA_PIN_PULL_DOWN>;
				nvidia,tristate = <TEGRA_PIN_ENABLE>;
				nvidia,enable-input = <TEGRA_PIN_DISABLE>;
			};

			sdmmc3_clk_po0 {
				nvidia,pins = "sdmmc3_clk_po0";
				nvidia,function = "rsvd1";
				nvidia,pull = <TEGRA_PIN_PULL_DOWN>;
				nvidia,tristate = <TEGRA_PIN_ENABLE>;
				nvidia,enable-input = <TEGRA_PIN_DISABLE>;
				nvidia,loopback = <TEGRA_PIN_DISABLE>;
			};

			sdmmc3_cmd_po1 {
				nvidia,pins = "sdmmc3_cmd_po1";
				nvidia,function = "rsvd1";
				nvidia,pull = <TEGRA_PIN_PULL_DOWN>;
				nvidia,tristate = <TEGRA_PIN_ENABLE>;
				nvidia,enable-input = <TEGRA_PIN_DISABLE>;
			};

			sdmmc3_dat0_po2 {
				nvidia,pins = "sdmmc3_dat0_po2";
				nvidia,function = "rsvd1";
				nvidia,pull = <TEGRA_PIN_PULL_DOWN>;
				nvidia,tristate = <TEGRA_PIN_ENABLE>;
				nvidia,enable-input = <TEGRA_PIN_DISABLE>;
			};

			sdmmc3_dat1_po3 {
				nvidia,pins = "sdmmc3_dat1_po3";
				nvidia,function = "rsvd1";
				nvidia,pull = <TEGRA_PIN_PULL_DOWN>;
				nvidia,tristate = <TEGRA_PIN_ENABLE>;
				nvidia,enable-input = <TEGRA_PIN_DISABLE>;
			};

			sdmmc3_dat2_po4 {
				nvidia,pins = "sdmmc3_dat2_po4";
				nvidia,function = "rsvd1";
				nvidia,pull = <TEGRA_PIN_PULL_DOWN>;
				nvidia,tristate = <TEGRA_PIN_ENABLE>;
				nvidia,enable-input = <TEGRA_PIN_DISABLE>;
			};

			sdmmc3_dat3_po5 {
				nvidia,pins = "sdmmc3_dat3_po5";
				nvidia,function = "rsvd1";
				nvidia,pull = <TEGRA_PIN_PULL_DOWN>;
				nvidia,tristate = <TEGRA_PIN_ENABLE>;
				nvidia,enable-input = <TEGRA_PIN_DISABLE>;
			};

			soc_gpio02_pg2 {
				nvidia,pins = "soc_gpio02_pg2";
				nvidia,function = "rsvd0";
				nvidia,pull = <TEGRA_PIN_PULL_DOWN>;
				nvidia,tristate = <TEGRA_PIN_ENABLE>;
				nvidia,enable-input = <TEGRA_PIN_DISABLE>;
				nvidia,lpdr = <TEGRA_PIN_DISABLE>;
			};

			soc_gpio03_pg3 {
				nvidia,pins = "soc_gpio03_pg3";
				nvidia,function = "rsvd0";
				nvidia,pull = <TEGRA_PIN_PULL_DOWN>;
				nvidia,tristate = <TEGRA_PIN_ENABLE>;
				nvidia,enable-input = <TEGRA_PIN_DISABLE>;
				nvidia,lpdr = <TEGRA_PIN_DISABLE>;
			};

			soc_gpio11_pg7 {
				nvidia,pins = "soc_gpio11_pg7";
				nvidia,function = "rsvd0";
				nvidia,pull = <TEGRA_PIN_PULL_DOWN>;
				nvidia,tristate = <TEGRA_PIN_ENABLE>;
				nvidia,enable-input = <TEGRA_PIN_DISABLE>;
				nvidia,lpdr = <TEGRA_PIN_DISABLE>;
			};

			soc_gpio12_ph0 {
				nvidia,pins = "soc_gpio12_ph0";
				nvidia,function = "rsvd0";
				nvidia,pull = <TEGRA_PIN_PULL_DOWN>;
				nvidia,tristate = <TEGRA_PIN_ENABLE>;
				nvidia,enable-input = <TEGRA_PIN_DISABLE>;
				nvidia,lpdr = <TEGRA_PIN_DISABLE>;
			};

			uart4_tx_ph3 {
				nvidia,pins = "uart4_tx_ph3";
				nvidia,function = "rsvd1";
				nvidia,pull = <TEGRA_PIN_PULL_DOWN>;
				nvidia,tristate = <TEGRA_PIN_ENABLE>;
				nvidia,enable-input = <TEGRA_PIN_DISABLE>;
				nvidia,lpdr = <TEGRA_PIN_DISABLE>;
			};

			uart4_rx_ph4 {
				nvidia,pins = "uart4_rx_ph4";
				nvidia,function = "rsvd1";
				nvidia,pull = <TEGRA_PIN_PULL_DOWN>;
				nvidia,tristate = <TEGRA_PIN_ENABLE>;
				nvidia,enable-input = <TEGRA_PIN_DISABLE>;
				nvidia,lpdr = <TEGRA_PIN_DISABLE>;
			};

			uart4_rts_ph5 {
				nvidia,pins = "uart4_rts_ph5";
				nvidia,function = "rsvd1";
				nvidia,pull = <TEGRA_PIN_PULL_DOWN>;
				nvidia,tristate = <TEGRA_PIN_ENABLE>;
				nvidia,enable-input = <TEGRA_PIN_DISABLE>;
				nvidia,lpdr = <TEGRA_PIN_DISABLE>;
			};

			uart4_cts_ph6 {
				nvidia,pins = "uart4_cts_ph6";
				nvidia,function = "rsvd1";
				nvidia,pull = <TEGRA_PIN_PULL_DOWN>;
				nvidia,tristate = <TEGRA_PIN_ENABLE>;
				nvidia,enable-input = <TEGRA_PIN_DISABLE>;
				nvidia,lpdr = <TEGRA_PIN_DISABLE>;
			};

			dap2_sclk_ph7 {
				nvidia,pins = "dap2_sclk_ph7";
				nvidia,function = "rsvd1";
				nvidia,pull = <TEGRA_PIN_PULL_DOWN>;
				nvidia,tristate = <TEGRA_PIN_ENABLE>;
				nvidia,enable-input = <TEGRA_PIN_DISABLE>;
				nvidia,lpdr = <TEGRA_PIN_DISABLE>;
			};

			dap2_dout_pi0 {
				nvidia,pins = "dap2_dout_pi0";
				nvidia,function = "rsvd1";
				nvidia,pull = <TEGRA_PIN_PULL_DOWN>;
				nvidia,tristate = <TEGRA_PIN_ENABLE>;
				nvidia,enable-input = <TEGRA_PIN_DISABLE>;
				nvidia,lpdr = <TEGRA_PIN_DISABLE>;
			};

			dap2_din_pi1 {
				nvidia,pins = "dap2_din_pi1";
				nvidia,function = "rsvd1";
				nvidia,pull = <TEGRA_PIN_PULL_DOWN>;
				nvidia,tristate = <TEGRA_PIN_ENABLE>;
				nvidia,enable-input = <TEGRA_PIN_DISABLE>;
				nvidia,lpdr = <TEGRA_PIN_DISABLE>;
			};

			dap2_fs_pi2 {
				nvidia,pins = "dap2_fs_pi2";
				nvidia,function = "rsvd1";
				nvidia,pull = <TEGRA_PIN_PULL_DOWN>;
				nvidia,tristate = <TEGRA_PIN_ENABLE>;
				nvidia,enable-input = <TEGRA_PIN_DISABLE>;
				nvidia,lpdr = <TEGRA_PIN_DISABLE>;
			};

			uart2_rts_px6 {
				nvidia,pins = "uart2_rts_px6";
				nvidia,function = "rsvd1";
				nvidia,pull = <TEGRA_PIN_PULL_DOWN>;
				nvidia,tristate = <TEGRA_PIN_ENABLE>;
				nvidia,enable-input = <TEGRA_PIN_DISABLE>;
				nvidia,lpdr = <TEGRA_PIN_DISABLE>;
			};

			uart2_cts_px7 {
				nvidia,pins = "uart2_cts_px7";
				nvidia,function = "rsvd1";
				nvidia,pull = <TEGRA_PIN_PULL_DOWN>;
				nvidia,tristate = <TEGRA_PIN_ENABLE>;
				nvidia,enable-input = <TEGRA_PIN_DISABLE>;
				nvidia,lpdr = <TEGRA_PIN_DISABLE>;
			};

			spi3_sck_py0 {
				nvidia,pins = "spi3_sck_py0";
				nvidia,function = "rsvd1";
				nvidia,pull = <TEGRA_PIN_PULL_DOWN>;
				nvidia,tristate = <TEGRA_PIN_ENABLE>;
				nvidia,enable-input = <TEGRA_PIN_DISABLE>;
				nvidia,io-high-voltage = <TEGRA_PIN_DISABLE>;
				nvidia,lpdr = <TEGRA_PIN_DISABLE>;
			};

			spi3_miso_py1 {
				nvidia,pins = "spi3_miso_py1";
				nvidia,function = "rsvd1";
				nvidia,pull = <TEGRA_PIN_PULL_DOWN>;
				nvidia,tristate = <TEGRA_PIN_ENABLE>;
				nvidia,enable-input = <TEGRA_PIN_DISABLE>;
				nvidia,io-high-voltage = <TEGRA_PIN_DISABLE>;
				nvidia,lpdr = <TEGRA_PIN_DISABLE>;
			};

			spi3_mosi_py2 {
				nvidia,pins = "spi3_mosi_py2";
				nvidia,function = "rsvd1";
				nvidia,pull = <TEGRA_PIN_PULL_DOWN>;
				nvidia,tristate = <TEGRA_PIN_ENABLE>;
				nvidia,enable-input = <TEGRA_PIN_DISABLE>;
				nvidia,io-high-voltage = <TEGRA_PIN_DISABLE>;
				nvidia,lpdr = <TEGRA_PIN_DISABLE>;
			};

			spi3_cs0_py3 {
				nvidia,pins = "spi3_cs0_py3";
				nvidia,function = "rsvd1";
				nvidia,pull = <TEGRA_PIN_PULL_DOWN>;
				nvidia,tristate = <TEGRA_PIN_ENABLE>;
				nvidia,enable-input = <TEGRA_PIN_DISABLE>;
				nvidia,io-high-voltage = <TEGRA_PIN_DISABLE>;
				nvidia,lpdr = <TEGRA_PIN_DISABLE>;
			};

			spi3_cs1_py4 {
				nvidia,pins = "spi3_cs1_py4";
				nvidia,function = "rsvd1";
				nvidia,pull = <TEGRA_PIN_PULL_DOWN>;
				nvidia,tristate = <TEGRA_PIN_ENABLE>;
				nvidia,enable-input = <TEGRA_PIN_DISABLE>;
				nvidia,io-high-voltage = <TEGRA_PIN_DISABLE>;
				nvidia,lpdr = <TEGRA_PIN_DISABLE>;
			};

			uart5_tx_py5 {
				nvidia,pins = "uart5_tx_py5";
				nvidia,function = "rsvd1";
				nvidia,pull = <TEGRA_PIN_PULL_DOWN>;
				nvidia,tristate = <TEGRA_PIN_ENABLE>;
				nvidia,enable-input = <TEGRA_PIN_DISABLE>;
				nvidia,lpdr = <TEGRA_PIN_DISABLE>;
			};

			uart5_rx_py6 {
				nvidia,pins = "uart5_rx_py6";
				nvidia,function = "rsvd1";
				nvidia,pull = <TEGRA_PIN_PULL_DOWN>;
				nvidia,tristate = <TEGRA_PIN_ENABLE>;
				nvidia,enable-input = <TEGRA_PIN_DISABLE>;
				nvidia,lpdr = <TEGRA_PIN_DISABLE>;
			};

			uart5_rts_py7 {
				nvidia,pins = "uart5_rts_py7";
				nvidia,function = "rsvd1";
				nvidia,pull = <TEGRA_PIN_PULL_DOWN>;
				nvidia,tristate = <TEGRA_PIN_ENABLE>;
				nvidia,enable-input = <TEGRA_PIN_DISABLE>;
				nvidia,lpdr = <TEGRA_PIN_DISABLE>;
			};

			uart5_cts_pz0 {
				nvidia,pins = "uart5_cts_pz0";
				nvidia,function = "rsvd1";
				nvidia,pull = <TEGRA_PIN_PULL_DOWN>;
				nvidia,tristate = <TEGRA_PIN_ENABLE>;
				nvidia,enable-input = <TEGRA_PIN_DISABLE>;
				nvidia,lpdr = <TEGRA_PIN_DISABLE>;
			};

			spi1_cs1_pz7 {
				nvidia,pins = "spi1_cs1_pz7";
				nvidia,function = "rsvd1";
				nvidia,pull = <TEGRA_PIN_PULL_DOWN>;
				nvidia,tristate = <TEGRA_PIN_ENABLE>;
				nvidia,enable-input = <TEGRA_PIN_DISABLE>;
				nvidia,lpdr = <TEGRA_PIN_DISABLE>;
			};

			vcomp_alert_pee1 {
				nvidia,pins = "vcomp_alert_pee1";
				nvidia,function = "rsvd1";
				nvidia,pull = <TEGRA_PIN_PULL_DOWN>;
				nvidia,tristate = <TEGRA_PIN_ENABLE>;
				nvidia,enable-input = <TEGRA_PIN_DISABLE>;
				nvidia,lpdr = <TEGRA_PIN_DISABLE>;
			};

			ao_retention_n_pee2 {
				nvidia,pins = "ao_retention_n_pee2";
				nvidia,function = "rsvd1";
				nvidia,pull = <TEGRA_PIN_PULL_DOWN>;
				nvidia,tristate = <TEGRA_PIN_ENABLE>;
				nvidia,enable-input = <TEGRA_PIN_DISABLE>;
				nvidia,io-high-voltage = <TEGRA_PIN_DISABLE>;
				nvidia,lpdr = <TEGRA_PIN_DISABLE>;
			};

			can1_dout_paa0 {
				nvidia,pins = "can1_dout_paa0";
				nvidia,function = "rsvd1";
				nvidia,pull = <TEGRA_PIN_PULL_DOWN>;
				nvidia,tristate = <TEGRA_PIN_ENABLE>;
				nvidia,enable-input = <TEGRA_PIN_DISABLE>;
			};

			can1_din_paa1 {
				nvidia,pins = "can1_din_paa1";
				nvidia,function = "rsvd1";
				nvidia,pull = <TEGRA_PIN_PULL_DOWN>;
				nvidia,tristate = <TEGRA_PIN_ENABLE>;
				nvidia,enable-input = <TEGRA_PIN_DISABLE>;
			};

			can0_dout_paa2 {
				nvidia,pins = "can0_dout_paa2";
				nvidia,function = "rsvd1";
				nvidia,pull = <TEGRA_PIN_PULL_DOWN>;
				nvidia,tristate = <TEGRA_PIN_ENABLE>;
				nvidia,enable-input = <TEGRA_PIN_DISABLE>;
			};

			can0_din_paa3 {
				nvidia,pins = "can0_din_paa3";
				nvidia,function = "rsvd1";
				nvidia,pull = <TEGRA_PIN_PULL_DOWN>;
				nvidia,tristate = <TEGRA_PIN_ENABLE>;
				nvidia,enable-input = <TEGRA_PIN_DISABLE>;
			};

			can0_en_paa5 {
				nvidia,pins = "can0_en_paa5";
				nvidia,function = "rsvd0";
				nvidia,pull = <TEGRA_PIN_PULL_DOWN>;
				nvidia,tristate = <TEGRA_PIN_ENABLE>;
				nvidia,enable-input = <TEGRA_PIN_DISABLE>;
			};

			can0_wake_paa6 {
				nvidia,pins = "can0_wake_paa6";
				nvidia,function = "rsvd0";
				nvidia,pull = <TEGRA_PIN_PULL_DOWN>;
				nvidia,tristate = <TEGRA_PIN_ENABLE>;
				nvidia,enable-input = <TEGRA_PIN_DISABLE>;
			};

			can1_stb_pbb0 {
				nvidia,pins = "can1_stb_pbb0";
				nvidia,function = "rsvd0";
				nvidia,pull = <TEGRA_PIN_PULL_DOWN>;
				nvidia,tristate = <TEGRA_PIN_ENABLE>;
				nvidia,enable-input = <TEGRA_PIN_DISABLE>;
			};

			can1_err_pbb3 {
				nvidia,pins = "can1_err_pbb3";
				nvidia,function = "rsvd0";
				nvidia,pull = <TEGRA_PIN_PULL_DOWN>;
				nvidia,tristate = <TEGRA_PIN_ENABLE>;
				nvidia,enable-input = <TEGRA_PIN_DISABLE>;
			};

			gen8_i2c_scl_pdd1 {
				nvidia,pins = "gen8_i2c_scl_pdd1";
				nvidia,function = "rsvd1";
				nvidia,pull = <TEGRA_PIN_PULL_DOWN>;
				nvidia,tristate = <TEGRA_PIN_ENABLE>;
				nvidia,enable-input = <TEGRA_PIN_DISABLE>;
				nvidia,io-high-voltage = <TEGRA_PIN_DISABLE>;
				nvidia,lpdr = <TEGRA_PIN_ENABLE>;
			};

			gen8_i2c_sda_pdd2 {
				nvidia,pins = "gen8_i2c_sda_pdd2";
				nvidia,function = "rsvd1";
				nvidia,pull = <TEGRA_PIN_PULL_DOWN>;
				nvidia,tristate = <TEGRA_PIN_ENABLE>;
				nvidia,enable-input = <TEGRA_PIN_DISABLE>;
				nvidia,io-high-voltage = <TEGRA_PIN_DISABLE>;
				nvidia,lpdr = <TEGRA_PIN_ENABLE>;
			};

			extperiph1_clk_pp0 {
				nvidia,pins = "extperiph1_clk_pp0";
				nvidia,function = "rsvd1";
				nvidia,pull = <TEGRA_PIN_PULL_DOWN>;
				nvidia,tristate = <TEGRA_PIN_ENABLE>;
				nvidia,enable-input = <TEGRA_PIN_DISABLE>;
				nvidia,lpdr = <TEGRA_PIN_DISABLE>;
			};

			extperiph2_clk_pp1 {
				nvidia,pins = "extperiph2_clk_pp1";
				nvidia,function = "rsvd1";
				nvidia,pull = <TEGRA_PIN_PULL_DOWN>;
				nvidia,tristate = <TEGRA_PIN_ENABLE>;
				nvidia,enable-input = <TEGRA_PIN_DISABLE>;
				nvidia,lpdr = <TEGRA_PIN_DISABLE>;
			};

			cam_i2c_scl_pp2 {
				nvidia,pins = "cam_i2c_scl_pp2";
				nvidia,function = "rsvd1";
				nvidia,pull = <TEGRA_PIN_PULL_DOWN>;
				nvidia,tristate = <TEGRA_PIN_ENABLE>;
				nvidia,enable-input = <TEGRA_PIN_DISABLE>;
				nvidia,io-high-voltage = <TEGRA_PIN_DISABLE>;
				nvidia,lpdr = <TEGRA_PIN_DISABLE>;
			};

			cam_i2c_sda_pp3 {
				nvidia,pins = "cam_i2c_sda_pp3";
				nvidia,function = "rsvd1";
				nvidia,pull = <TEGRA_PIN_PULL_DOWN>;
				nvidia,tristate = <TEGRA_PIN_ENABLE>;
				nvidia,enable-input = <TEGRA_PIN_DISABLE>;
				nvidia,io-high-voltage = <TEGRA_PIN_DISABLE>;
				nvidia,lpdr = <TEGRA_PIN_DISABLE>;
			};

			soc_gpio23_pq3 {
				nvidia,pins = "soc_gpio23_pq3";
				nvidia,function = "rsvd0";
				nvidia,pull = <TEGRA_PIN_PULL_DOWN>;
				nvidia,tristate = <TEGRA_PIN_ENABLE>;
				nvidia,enable-input = <TEGRA_PIN_DISABLE>;
				nvidia,lpdr = <TEGRA_PIN_DISABLE>;
			};

			soc_gpio41_pq5 {
				nvidia,pins = "soc_gpio41_pq5";
				nvidia,function = "rsvd2";
				nvidia,pull = <TEGRA_PIN_PULL_DOWN>;
				nvidia,tristate = <TEGRA_PIN_ENABLE>;
				nvidia,enable-input = <TEGRA_PIN_DISABLE>;
				nvidia,io-high-voltage = <TEGRA_PIN_DISABLE>;
				nvidia,lpdr = <TEGRA_PIN_DISABLE>;
			};

			soc_gpio42_pq6 {
				nvidia,pins = "soc_gpio42_pq6";
				nvidia,function = "rsvd2";
				nvidia,pull = <TEGRA_PIN_PULL_DOWN>;
				nvidia,tristate = <TEGRA_PIN_ENABLE>;
				nvidia,enable-input = <TEGRA_PIN_DISABLE>;
				nvidia,io-high-voltage = <TEGRA_PIN_DISABLE>;
				nvidia,lpdr = <TEGRA_PIN_DISABLE>;
			};

			soc_gpio43_pq7 {
				nvidia,pins = "soc_gpio43_pq7";
				nvidia,function = "rsvd2";
				nvidia,pull = <TEGRA_PIN_PULL_DOWN>;
				nvidia,tristate = <TEGRA_PIN_ENABLE>;
				nvidia,enable-input = <TEGRA_PIN_DISABLE>;
				nvidia,io-high-voltage = <TEGRA_PIN_ENABLE>;
				nvidia,lpdr = <TEGRA_PIN_DISABLE>;
			};

			soc_gpio44_pr0 {
				nvidia,pins = "soc_gpio44_pr0";
				nvidia,function = "rsvd2";
				nvidia,pull = <TEGRA_PIN_PULL_DOWN>;
				nvidia,tristate = <TEGRA_PIN_ENABLE>;
				nvidia,enable-input = <TEGRA_PIN_DISABLE>;
				nvidia,io-high-voltage = <TEGRA_PIN_DISABLE>;
				nvidia,lpdr = <TEGRA_PIN_DISABLE>;
			};

			soc_gpio45_pr1 {
				nvidia,pins = "soc_gpio45_pr1";
				nvidia,function = "rsvd1";
				nvidia,pull = <TEGRA_PIN_PULL_DOWN>;
				nvidia,tristate = <TEGRA_PIN_ENABLE>;
				nvidia,enable-input = <TEGRA_PIN_DISABLE>;
				nvidia,io-high-voltage = <TEGRA_PIN_DISABLE>;
				nvidia,lpdr = <TEGRA_PIN_DISABLE>;
			};

			uart1_tx_pr2 {
				nvidia,pins = "uart1_tx_pr2";
				nvidia,function = "rsvd1";
				nvidia,pull = <TEGRA_PIN_PULL_DOWN>;
				nvidia,tristate = <TEGRA_PIN_ENABLE>;
				nvidia,enable-input = <TEGRA_PIN_DISABLE>;
				nvidia,io-high-voltage = <TEGRA_PIN_DISABLE>;
				nvidia,lpdr = <TEGRA_PIN_DISABLE>;
			};

			uart1_rx_pr3 {
				nvidia,pins = "uart1_rx_pr3";
				nvidia,function = "rsvd1";
				nvidia,pull = <TEGRA_PIN_PULL_DOWN>;
				nvidia,tristate = <TEGRA_PIN_ENABLE>;
				nvidia,enable-input = <TEGRA_PIN_DISABLE>;
				nvidia,io-high-voltage = <TEGRA_PIN_DISABLE>;
				nvidia,lpdr = <TEGRA_PIN_DISABLE>;
			};

			uart1_rts_pr4 {
				nvidia,pins = "uart1_rts_pr4";
				nvidia,function = "rsvd1";
				nvidia,pull = <TEGRA_PIN_PULL_DOWN>;
				nvidia,tristate = <TEGRA_PIN_ENABLE>;
				nvidia,enable-input = <TEGRA_PIN_DISABLE>;
				nvidia,lpdr = <TEGRA_PIN_DISABLE>;
			};

			uart1_cts_pr5 {
				nvidia,pins = "uart1_cts_pr5";
				nvidia,function = "rsvd1";
				nvidia,pull = <TEGRA_PIN_PULL_DOWN>;
				nvidia,tristate = <TEGRA_PIN_ENABLE>;
				nvidia,enable-input = <TEGRA_PIN_DISABLE>;
				nvidia,lpdr = <TEGRA_PIN_DISABLE>;
			};

			dap6_dout_pa1 {
				nvidia,pins = "dap6_dout_pa1";
				nvidia,function = "rsvd2";
				nvidia,pull = <TEGRA_PIN_PULL_DOWN>;
				nvidia,tristate = <TEGRA_PIN_ENABLE>;
				nvidia,enable-input = <TEGRA_PIN_DISABLE>;
			};

			dap6_fs_pa3 {
				nvidia,pins = "dap6_fs_pa3";
				nvidia,function = "rsvd2";
				nvidia,pull = <TEGRA_PIN_PULL_DOWN>;
				nvidia,tristate = <TEGRA_PIN_ENABLE>;
				nvidia,enable-input = <TEGRA_PIN_DISABLE>;
			};

			dap4_sclk_pa4 {
				nvidia,pins = "dap4_sclk_pa4";
				nvidia,function = "rsvd2";
				nvidia,pull = <TEGRA_PIN_PULL_DOWN>;
				nvidia,tristate = <TEGRA_PIN_ENABLE>;
				nvidia,enable-input = <TEGRA_PIN_ENABLE>;
			};

			dap4_dout_pa5 {
				nvidia,pins = "dap4_dout_pa5";
				nvidia,function = "rsvd2";
				nvidia,pull = <TEGRA_PIN_PULL_DOWN>;
				nvidia,tristate = <TEGRA_PIN_ENABLE>;
				nvidia,enable-input = <TEGRA_PIN_DISABLE>;
			};

			dap4_din_pa6 {
				nvidia,pins = "dap4_din_pa6";
				nvidia,function = "rsvd2";
				nvidia,pull = <TEGRA_PIN_PULL_DOWN>;
				nvidia,tristate = <TEGRA_PIN_ENABLE>;
				nvidia,enable-input = <TEGRA_PIN_DISABLE>;
			};

			dap4_fs_pa7 {
				nvidia,pins = "dap4_fs_pa7";
				nvidia,function = "rsvd2";
				nvidia,pull = <TEGRA_PIN_PULL_DOWN>;
				nvidia,tristate = <TEGRA_PIN_ENABLE>;
				nvidia,enable-input = <TEGRA_PIN_ENABLE>;
			};

			ufs0_ref_clk_pff0 {
				nvidia,pins = "ufs0_ref_clk_pff0";
				nvidia,function = "rsvd1";
				nvidia,pull = <TEGRA_PIN_PULL_DOWN>;
				nvidia,tristate = <TEGRA_PIN_ENABLE>;
				nvidia,enable-input = <TEGRA_PIN_DISABLE>;
			};

			ufs0_rst_pff1 {
				nvidia,pins = "ufs0_rst_pff1";
				nvidia,function = "rsvd1";
				nvidia,pull = <TEGRA_PIN_PULL_DOWN>;
				nvidia,tristate = <TEGRA_PIN_ENABLE>;
				nvidia,enable-input = <TEGRA_PIN_DISABLE>;
			};

			pex_l0_clkreq_n_pk0 {
				nvidia,pins = "pex_l0_clkreq_n_pk0";
				nvidia,function = "rsvd1";
				nvidia,pull = <TEGRA_PIN_PULL_DOWN>;
				nvidia,tristate = <TEGRA_PIN_ENABLE>;
				nvidia,enable-input = <TEGRA_PIN_DISABLE>;
				nvidia,io-high-voltage = <TEGRA_PIN_ENABLE>;
				nvidia,lpdr = <TEGRA_PIN_ENABLE>;
			};

			pex_l0_rst_n_pk1 {
				nvidia,pins = "pex_l0_rst_n_pk1";
				nvidia,function = "rsvd1";
				nvidia,pull = <TEGRA_PIN_PULL_DOWN>;
				nvidia,tristate = <TEGRA_PIN_ENABLE>;
				nvidia,enable-input = <TEGRA_PIN_DISABLE>;
				nvidia,io-high-voltage = <TEGRA_PIN_ENABLE>;
				nvidia,lpdr = <TEGRA_PIN_ENABLE>;
			};

			pex_l1_clkreq_n_pk2 {
				nvidia,pins = "pex_l1_clkreq_n_pk2";
				nvidia,function = "rsvd1";
				nvidia,pull = <TEGRA_PIN_PULL_DOWN>;
				nvidia,tristate = <TEGRA_PIN_ENABLE>;
				nvidia,enable-input = <TEGRA_PIN_DISABLE>;
				nvidia,io-high-voltage = <TEGRA_PIN_ENABLE>;
				nvidia,lpdr = <TEGRA_PIN_ENABLE>;
			};

			pex_l1_rst_n_pk3 {
				nvidia,pins = "pex_l1_rst_n_pk3";
				nvidia,function = "rsvd1";
				nvidia,pull = <TEGRA_PIN_PULL_DOWN>;
				nvidia,tristate = <TEGRA_PIN_ENABLE>;
				nvidia,enable-input = <TEGRA_PIN_DISABLE>;
				nvidia,io-high-voltage = <TEGRA_PIN_ENABLE>;
				nvidia,lpdr = <TEGRA_PIN_ENABLE>;
			};

			pex_l2_clkreq_n_pk4 {
				nvidia,pins = "pex_l2_clkreq_n_pk4";
				nvidia,function = "rsvd1";
				nvidia,pull = <TEGRA_PIN_PULL_DOWN>;
				nvidia,tristate = <TEGRA_PIN_ENABLE>;
				nvidia,enable-input = <TEGRA_PIN_DISABLE>;
				nvidia,io-high-voltage = <TEGRA_PIN_ENABLE>;
				nvidia,lpdr = <TEGRA_PIN_ENABLE>;
			};

			pex_l2_rst_n_pk5 {
				nvidia,pins = "pex_l2_rst_n_pk5";
				nvidia,function = "rsvd1";
				nvidia,pull = <TEGRA_PIN_PULL_DOWN>;
				nvidia,tristate = <TEGRA_PIN_ENABLE>;
				nvidia,enable-input = <TEGRA_PIN_DISABLE>;
				nvidia,io-high-voltage = <TEGRA_PIN_ENABLE>;
				nvidia,lpdr = <TEGRA_PIN_ENABLE>;
			};

			pex_l3_clkreq_n_pk6 {
				nvidia,pins = "pex_l3_clkreq_n_pk6";
				nvidia,function = "rsvd1";
				nvidia,pull = <TEGRA_PIN_PULL_DOWN>;
				nvidia,tristate = <TEGRA_PIN_ENABLE>;
				nvidia,enable-input = <TEGRA_PIN_DISABLE>;
				nvidia,io-high-voltage = <TEGRA_PIN_ENABLE>;
				nvidia,lpdr = <TEGRA_PIN_ENABLE>;
			};

			pex_l3_rst_n_pk7 {
				nvidia,pins = "pex_l3_rst_n_pk7";
				nvidia,function = "rsvd1";
				nvidia,pull = <TEGRA_PIN_PULL_DOWN>;
				nvidia,tristate = <TEGRA_PIN_ENABLE>;
				nvidia,enable-input = <TEGRA_PIN_DISABLE>;
				nvidia,io-high-voltage = <TEGRA_PIN_ENABLE>;
				nvidia,lpdr = <TEGRA_PIN_ENABLE>;
			};

			pex_l4_clkreq_n_pl0 {
				nvidia,pins = "pex_l4_clkreq_n_pl0";
				nvidia,function = "rsvd1";
				nvidia,pull = <TEGRA_PIN_PULL_DOWN>;
				nvidia,tristate = <TEGRA_PIN_ENABLE>;
				nvidia,enable-input = <TEGRA_PIN_DISABLE>;
				nvidia,io-high-voltage = <TEGRA_PIN_ENABLE>;
				nvidia,lpdr = <TEGRA_PIN_ENABLE>;
			};

			pex_l4_rst_n_pl1 {
				nvidia,pins = "pex_l4_rst_n_pl1";
				nvidia,function = "rsvd1";
				nvidia,pull = <TEGRA_PIN_PULL_DOWN>;
				nvidia,tristate = <TEGRA_PIN_ENABLE>;
				nvidia,enable-input = <TEGRA_PIN_DISABLE>;
				nvidia,io-high-voltage = <TEGRA_PIN_ENABLE>;
				nvidia,lpdr = <TEGRA_PIN_ENABLE>;
			};

			pex_wake_n_pl2 {
				nvidia,pins = "pex_wake_n_pl2";
				nvidia,function = "rsvd0";
				nvidia,pull = <TEGRA_PIN_PULL_DOWN>;
				nvidia,tristate = <TEGRA_PIN_ENABLE>;
				nvidia,enable-input = <TEGRA_PIN_DISABLE>;
				nvidia,io-high-voltage = <TEGRA_PIN_ENABLE>;
				nvidia,lpdr = <TEGRA_PIN_ENABLE>;
			};

			sata_dev_slp_pl3 {
				nvidia,pins = "sata_dev_slp_pl3";
				nvidia,function = "rsvd1";
				nvidia,pull = <TEGRA_PIN_PULL_DOWN>;
				nvidia,tristate = <TEGRA_PIN_ENABLE>;
				nvidia,enable-input = <TEGRA_PIN_DISABLE>;
				nvidia,io-high-voltage = <TEGRA_PIN_DISABLE>;
				nvidia,lpdr = <TEGRA_PIN_DISABLE>;
			};

			pex_l5_clkreq_n {
				nvidia,pins = "pex_l5_clkreq_n";
				nvidia,function = "rsvd1";
				nvidia,pull = <TEGRA_PIN_PULL_DOWN>;
				nvidia,tristate = <TEGRA_PIN_ENABLE>;
				nvidia,enable-input = <TEGRA_PIN_DISABLE>;
				nvidia,io-high-voltage = <TEGRA_PIN_ENABLE>;
				nvidia,lpdr = <TEGRA_PIN_ENABLE>;
			};

			pex_l5_rst_n {
				nvidia,pins = "pex_l5_rst_n";
				nvidia,function = "rsvd1";
				nvidia,pull = <TEGRA_PIN_PULL_DOWN>;
				nvidia,tristate = <TEGRA_PIN_ENABLE>;
				nvidia,enable-input = <TEGRA_PIN_DISABLE>;
				nvidia,io-high-voltage = <TEGRA_PIN_ENABLE>;
				nvidia,lpdr = <TEGRA_PIN_ENABLE>;
			};

			dp_aux_ch0_hpd_pm0 {
				nvidia,pins = "dp_aux_ch0_hpd_pm0";
				nvidia,function = "rsvd1";
				nvidia,pull = <TEGRA_PIN_PULL_DOWN>;
				nvidia,tristate = <TEGRA_PIN_ENABLE>;
				nvidia,enable-input = <TEGRA_PIN_DISABLE>;
				nvidia,io-high-voltage = <TEGRA_PIN_DISABLE>;
				nvidia,lpdr = <TEGRA_PIN_DISABLE>;
			};

			dp_aux_ch1_hpd_pm1 {
				nvidia,pins = "dp_aux_ch1_hpd_pm1";
				nvidia,function = "rsvd1";
				nvidia,pull = <TEGRA_PIN_PULL_DOWN>;
				nvidia,tristate = <TEGRA_PIN_ENABLE>;
				nvidia,enable-input = <TEGRA_PIN_DISABLE>;
				nvidia,io-high-voltage = <TEGRA_PIN_DISABLE>;
				nvidia,lpdr = <TEGRA_PIN_DISABLE>;
			};

			dp_aux_ch2_hpd_pm2 {
				nvidia,pins = "dp_aux_ch2_hpd_pm2";
				nvidia,function = "rsvd2";
				nvidia,pull = <TEGRA_PIN_PULL_DOWN>;
				nvidia,tristate = <TEGRA_PIN_ENABLE>;
				nvidia,enable-input = <TEGRA_PIN_DISABLE>;
				nvidia,io-high-voltage = <TEGRA_PIN_DISABLE>;
			};

			hdmi_cec_pm4 {
				nvidia,pins = "hdmi_cec_pm4";
				nvidia,function = "rsvd1";
				nvidia,pull = <TEGRA_PIN_PULL_DOWN>;
				nvidia,tristate = <TEGRA_PIN_ENABLE>;
				nvidia,enable-input = <TEGRA_PIN_DISABLE>;
				nvidia,io-high-voltage = <TEGRA_PIN_ENABLE>;
				nvidia,lpdr = <TEGRA_PIN_DISABLE>;
			};

			soc_gpio50_pm5 {
				nvidia,pins = "soc_gpio50_pm5";
				nvidia,function = "rsvd0";
				nvidia,pull = <TEGRA_PIN_PULL_DOWN>;
				nvidia,tristate = <TEGRA_PIN_ENABLE>;
				nvidia,enable-input = <TEGRA_PIN_DISABLE>;
				nvidia,lpdr = <TEGRA_PIN_DISABLE>;
			};

			soc_gpio52_pm7 {
				nvidia,pins = "soc_gpio52_pm7";
				nvidia,function = "rsvd0";
				nvidia,pull = <TEGRA_PIN_PULL_DOWN>;
				nvidia,tristate = <TEGRA_PIN_ENABLE>;
				nvidia,enable-input = <TEGRA_PIN_DISABLE>;
				nvidia,lpdr = <TEGRA_PIN_DISABLE>;
			};
		};

		drive_default: drive {
		};
	};
};
